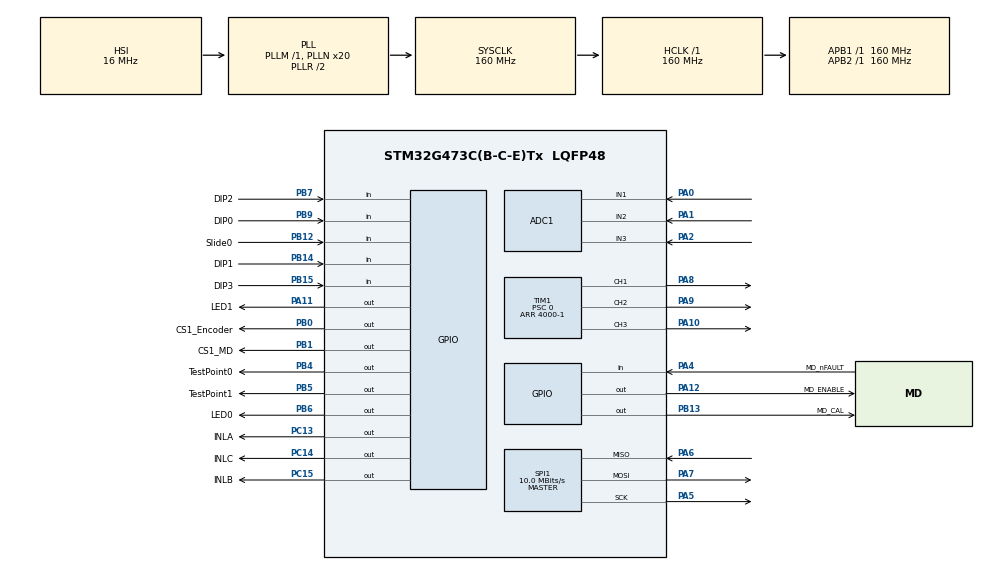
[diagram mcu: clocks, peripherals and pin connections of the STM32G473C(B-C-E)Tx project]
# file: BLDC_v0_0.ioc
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ADC1.DiscontinuousConvMode=DISABLE
ADC1.EnableInjectedConversion=ENABLE
ADC1.EnableRegularConversion=DISABLE
ADC1.ExternalTrigInjecConv=ADC_EXTERNALTRIGINJEC_T1_TRGO2
ADC1.InjNumberOfConversion=3
ADC1.InjectedChannel-3\#ChannelInjectedConversion=ADC_CHANNEL_1
ADC1.InjectedChannel-4\#ChannelInjectedConversion=ADC_CHANNEL_2
ADC1.InjectedChannel-5\#ChannelInjectedConversion=ADC_CHANNEL_3
ADC1.InjectedOffsetNumber-3\#ChannelInjectedConversion=ADC_OFFSET_NONE
ADC1.InjectedOffsetNumber-4\#ChannelInjectedConversion=ADC_OFFSET_NONE
ADC1.InjectedOffsetNumber-5\#ChannelInjectedConversion=ADC_OFFSET_NONE
ADC1.InjectedRank-3\#ChannelInjectedConversion=1
ADC1.InjectedRank-4\#ChannelInjectedConversion=2
ADC1.InjectedRank-5\#ChannelInjectedConversion=3
ADC1.InjectedSamplingTime-3\#ChannelInjectedConversion=ADC_SAMPLETIME_12CYCLES_5
ADC1.InjectedSamplingTime-4\#ChannelInjectedConversion=ADC_SAMPLETIME_12CYCLES_5
ADC1.InjectedSamplingTime-5\#ChannelInjectedConversion=ADC_SAMPLETIME_12CYCLES_5
ADC1.OversamplingMode=DISABLE
ADC1.Rank1_Channel=ADC_CHANNEL_1
ADC1.Rank2_Channel=ADC_CHANNEL_2
ADC1.Rank3_Channel=ADC_CHANNEL_3
ADC1.master=1
Mcu.Family=STM32G4
Mcu.Name=STM32G473C(B-C-E)Tx
Mcu.Package=LQFP48
NVIC.ADC1_2_IRQn=true\:8\:0\:true\:false\:true\:true\:true\:true
NVIC.PriorityGroup=NVIC_PRIORITYGROUP_4
NVIC.TIM1_CC_IRQn=true\:7\:0\:true\:false\:true\:true\:true\:true
NVIC.TIM3_IRQn=true\:6\:0\:true\:false\:true\:true\:true\:true
PA0.Mode=IN1-Single-Ended
PA0.Signal=ADC1_IN1
PA1.Mode=IN2-Single-Ended
PA1.Signal=ADC1_IN2
PA10.Signal=S_TIM1_CH3
PA11.GPIO_Label=LED1
PA11.Signal=GPIO_Output
PA12.GPIO_Label=MD_ENABLE
PA12.Signal=GPIO_Output
PA13.Mode=Trace_Asynchronous_SW
PA13.Signal=SYS_JTMS-SWDIO
PA14.Mode=Trace_Asynchronous_SW
PA14.Signal=SYS_JTCK-SWCLK
PA2.Mode=IN3-Single-Ended
PA2.Signal=ADC1_IN3
PA4.GPIO_Label=MD_nFAULT
PA4.Signal=GPIO_Input
PA5.GPIO_Speed=GPIO_SPEED_FREQ_MEDIUM
PA5.Mode=Full_Duplex_Master
PA5.Signal=SPI1_SCK
PA6.GPIO_Speed=GPIO_SPEED_FREQ_MEDIUM
PA6.Mode=Full_Duplex_Master
PA6.Signal=SPI1_MISO
PA7.GPIO_Speed=GPIO_SPEED_FREQ_MEDIUM
PA7.Mode=Full_Duplex_Master
PA7.Signal=SPI1_MOSI
PA8.Signal=S_TIM1_CH1
PA9.Signal=S_TIM1_CH2
PB0.GPIO_Label=CS1_Encoder
PB0.PinState=GPIO_PIN_SET
PB0.Signal=GPIO_Output
PB1.GPIO_Label=CS1_MD
PB1.PinState=GPIO_PIN_SET
PB1.Signal=GPIO_Output
PB12.GPIO_Label=Slide0
PB12.Signal=GPIO_Input
PB13.GPIO_Label=MD_CAL
PB13.Signal=GPIO_Output
PB14.GPIO_Label=DIP1
PB14.Signal=GPIO_Input
PB15.GPIO_Label=DIP3
PB15.Signal=GPIO_Input
PB3.Mode=Trace_Asynchronous_SW
PB3.Signal=SYS_JTDO-SWO
PB4.GPIO_Label=TestPoint0
PB4.Signal=GPIO_Output
PB5.GPIO_Label=TestPoint1
PB5.Signal=GPIO_Output
PB6.GPIO_Label=LED0
PB6.Signal=GPIO_Output
PB7.GPIO_Label=DIP2
PB7.Signal=GPIO_Input
PB9.GPIO_Label=DIP0
PB9.Signal=GPIO_Input
PC13.GPIO_Label=INLA
PC13.Signal=GPIO_Output
PC14-OSC32_IN.GPIO_Label=INLC
PC14-OSC32_IN.Signal=GPIO_Output
PC15-OSC32_OUT.GPIO_Label=INLB
PC15-OSC32_OUT.Signal=GPIO_Output
PF0-OSC_IN.Mode=HSE-External-Oscillator
PF0-OSC_IN.Signal=RCC_OSC_IN
PF1-OSC_OUT.Mode=HSE-External-Oscillator
PF1-OSC_OUT.Signal=RCC_OSC_OUT
ProjectManager.HeapSize=0x200
ProjectManager.StackSize=0x400
ProjectManager.TargetToolchain=STM32CubeIDE
RCC.ADC12Freq_Value=160000000
RCC.ADC345Freq_Value=160000000
RCC.AHBFreq_Value=160000000
RCC.APB1Freq_Value=160000000
RCC.APB1TimFreq_Value=160000000
RCC.APB2Freq_Value=160000000
RCC.APB2TimFreq_Value=160000000
RCC.CortexFreq_Value=160000000
RCC.EXTERNAL_CLOCK_VALUE=12288000
RCC.HCLKFreq_Value=160000000
RCC.HSE_VALUE=16000000
RCC.HSI48_VALUE=48000000
RCC.HSI_VALUE=16000000
RCC.LSE_VALUE=32768
RCC.PLLN=20
RCC.SYSCLKFreq_VALUE=160000000
RCC.SYSCLKSource=RCC_SYSCLKSOURCE_PLLCLK
RCC.USBFreq_Value=160000000
RCC.VCOOutputFreq_Value=320000000
SH.S_TIM1_CH1.0=TIM1_CH1,PWM Generation1 CH1
SH.S_TIM1_CH2.0=TIM1_CH2,PWM Generation2 CH2
SH.S_TIM1_CH3.0=TIM1_CH3,PWM Generation3 CH3
SPI1.BaudRatePrescaler=SPI_BAUDRATEPRESCALER_16
SPI1.CLKPhase=SPI_PHASE_2EDGE
SPI1.CLKPolarity=SPI_POLARITY_LOW
SPI1.CalculateBaudRate=10.0 MBits/s
SPI1.DataSize=SPI_DATASIZE_16BIT
SPI1.Direction=SPI_DIRECTION_2LINES
SPI1.Mode=SPI_MODE_MASTER
SPI1.VirtualType=VM_MASTER
TIM1.Channel-PWM\ Generation1\ CH1=TIM_CHANNEL_1
TIM1.Channel-PWM\ Generation2\ CH2=TIM_CHANNEL_2
TIM1.Channel-PWM\ Generation3\ CH3=TIM_CHANNEL_3
TIM1.Channel-PWM\ Generation4\ No\ Output=TIM_CHANNEL_4
TIM1.CounterMode=TIM_COUNTERMODE_CENTERALIGNED3
TIM1.OCMode_PWM-PWM\ Generation4\ No\ Output=TIM_OCMODE_PWM2
TIM1.PeriodNoDither=4000-1
TIM1.Prescaler=0
TIM1.TIM_MasterOutputTrigger=TIM_TRGO_UPDATE
TIM1.TIM_MasterOutputTrigger2=TIM_TRGO2_OC4REF
TIM3.Channel-PWM\ Generation1\ CH1=TIM_CHANNEL_1
TIM3.Channel-PWM\ Generation2\ CH2=TIM_CHANNEL_2
TIM3.Channel-PWM\ Generation3\ CH3=TIM_CHANNEL_3
TIM3.PeriodNoDither=65536-1
TIM3.Prescaler=15
VP_CORDIC_VS_CORDIC.Mode=CORDIC_Activate
VP_FMAC_VS_FMAC.Mode=FMAC_Activate
VP_SYS_VS_DBSignals.Mode=DisableDeadBatterySignals
VP_TIM1_VS_ClockSourceINT.Mode=Internal
VP_TIM1_VS_no_output4.Mode=PWM Generation4 No Output
VP_TIM3_VS_ClockSourceINT.Mode=Internal
board=custom

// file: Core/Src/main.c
/* USER CODE BEGIN Header */
/**
  ******************************************************************************
  * @file           : main.c
  * @brief          : Main program body
  ******************************************************************************
  * @attention
  *
  * Copyright (c) 2025 STMicroelectronics.
  * All rights reserved.
  *
  * This software is licensed under terms that can be found in the LICENSE file
  * in the root directory of this software component.
  * If no LICENSE file comes with this software, it is provided AS-IS.
  *
  ******************************************************************************
  */
/* USER CODE END Header */
#include "main.h"

/* USER CODE BEGIN Includes */

#include "Driver.h"
#include "AS5047P.h"
#include "DRV8323S.h"

#include <stdio.h>
#include <stdlib.h>
#include <stdbool.h>
#include <math.h>
#include <stm32g4xx_hal_cordic.h>

/* USER CODE END Includes */

ADC_HandleTypeDef hadc1;

CORDIC_HandleTypeDef hcordic;

FMAC_HandleTypeDef hfmac;

SPI_HandleTypeDef hspi1;

TIM_HandleTypeDef htim1;
TIM_HandleTypeDef htim3;

void SystemClock_Config(void);
static void MX_GPIO_Init(void);
static void MX_SPI1_Init(void);
static void MX_TIM3_Init(void);
static void MX_TIM1_Init(void);
static void MX_ADC1_Init(void);
static void MX_CORDIC_Init(void);
static void MX_FMAC_Init(void);

int main(void)
{

  /* MCU Configuration--------------------------------------------------------*/

  /* Reset of all peripherals, Initializes the Flash interface and the Systick. */
  HAL_Init();

  /* Configure the system clock */
  SystemClock_Config();

  /* Initialize all configured peripherals */
  MX_GPIO_Init();
  MX_SPI1_Init();
  MX_TIM3_Init();
  MX_TIM1_Init();
  MX_ADC1_Init();
  MX_CORDIC_Init();
  MX_FMAC_Init();

  /* Infinite loop */
  while (1)
  {

  }
}

void SystemClock_Config(void)
{
  RCC_OscInitTypeDef RCC_OscInitStruct = {0};
  RCC_ClkInitTypeDef RCC_ClkInitStruct = {0};

  /** Configure the main internal regulator output voltage
  */
  HAL_PWREx_ControlVoltageScaling(PWR_REGULATOR_VOLTAGE_SCALE1_BOOST);

  /** Initializes the RCC Oscillators according to the specified parameters
  * in the RCC_OscInitTypeDef structure.
  */
  RCC_OscInitStruct.OscillatorType = RCC_OSCILLATORTYPE_HSI;
  RCC_OscInitStruct.HSIState = RCC_HSI_ON;
  RCC_OscInitStruct.HSICalibrationValue = RCC_HSICALIBRATION_DEFAULT;
  RCC_OscInitStruct.PLL.PLLState = RCC_PLL_ON;
  RCC_OscInitStruct.PLL.PLLSource = RCC_PLLSOURCE_HSI;
  RCC_OscInitStruct.PLL.PLLM = RCC_PLLM_DIV1;
  RCC_OscInitStruct.PLL.PLLN = 20;
  RCC_OscInitStruct.PLL.PLLP = RCC_PLLP_DIV2;
  RCC_OscInitStruct.PLL.PLLQ = RCC_PLLQ_DIV2;
  RCC_OscInitStruct.PLL.PLLR = RCC_PLLR_DIV2;
  if (HAL_RCC_OscConfig(&RCC_OscInitStruct) != HAL_OK)
  {
    Error_Handler();
  }

  /** Initializes the CPU, AHB and APB buses clocks
  */
  RCC_ClkInitStruct.ClockType = RCC_CLOCKTYPE_HCLK|RCC_CLOCKTYPE_SYSCLK
                              |RCC_CLOCKTYPE_PCLK1|RCC_CLOCKTYPE_PCLK2;
  RCC_ClkInitStruct.SYSCLKSource = RCC_SYSCLKSOURCE_PLLCLK;
  RCC_ClkInitStruct.AHBCLKDivider = RCC_SYSCLK_DIV1;
  RCC_ClkInitStruct.APB1CLKDivider = RCC_HCLK_DIV1;
  RCC_ClkInitStruct.APB2CLKDivider = RCC_HCLK_DIV1;

  if (HAL_RCC_ClockConfig(&RCC_ClkInitStruct, FLASH_LATENCY_4) != HAL_OK)
  {
    Error_Handler();
  }
}

static void MX_ADC1_Init(void)
{

  ADC_MultiModeTypeDef multimode = {0};
  ADC_InjectionConfTypeDef sConfigInjected = {0};

  /** Common config
  */
  hadc1.Instance = ADC1;
  hadc1.Init.ClockPrescaler = ADC_CLOCK_SYNC_PCLK_DIV4;
  hadc1.Init.Resolution = ADC_RESOLUTION_12B;
  hadc1.Init.DataAlign = ADC_DATAALIGN_RIGHT;
  hadc1.Init.GainCompensation = 0;
  hadc1.Init.ScanConvMode = ADC_SCAN_ENABLE;
  hadc1.Init.EOCSelection = ADC_EOC_SINGLE_CONV;
  hadc1.Init.LowPowerAutoWait = DISABLE;
  hadc1.Init.ContinuousConvMode = DISABLE;
  hadc1.Init.NbrOfConversion = 1;
  hadc1.Init.DiscontinuousConvMode = DISABLE;
  hadc1.Init.DMAContinuousRequests = DISABLE;
  hadc1.Init.Overrun = ADC_OVR_DATA_PRESERVED;
  hadc1.Init.OversamplingMode = DISABLE;
  if (HAL_ADC_Init(&hadc1) != HAL_OK)
  {
    Error_Handler();
  }

  /** Configure the ADC multi-mode
  */
  multimode.Mode = ADC_MODE_INDEPENDENT;
  if (HAL_ADCEx_MultiModeConfigChannel(&hadc1, &multimode) != HAL_OK)
  {
    Error_Handler();
  }

  /** Configure Injected Channel
  */
  sConfigInjected.InjectedChannel = ADC_CHANNEL_1;
  sConfigInjected.InjectedRank = ADC_INJECTED_RANK_1;
  sConfigInjected.InjectedSamplingTime = ADC_SAMPLETIME_12CYCLES_5;
  sConfigInjected.InjectedSingleDiff = ADC_SINGLE_ENDED;
  sConfigInjected.InjectedOffsetNumber = ADC_OFFSET_NONE;
  sConfigInjected.InjectedOffset = 0;
  sConfigInjected.InjectedNbrOfConversion = 3;
  sConfigInjected.InjectedDiscontinuousConvMode = DISABLE;
  sConfigInjected.AutoInjectedConv = DISABLE;
  sConfigInjected.QueueInjectedContext = DISABLE;
  sConfigInjected.ExternalTrigInjecConv = ADC_EXTERNALTRIGINJEC_T1_TRGO2;
  sConfigInjected.ExternalTrigInjecConvEdge = ADC_EXTERNALTRIGINJECCONV_EDGE_RISING;
  sConfigInjected.InjecOversamplingMode = DISABLE;
  if (HAL_ADCEx_InjectedConfigChannel(&hadc1, &sConfigInjected) != HAL_OK)
  {
    Error_Handler();
  }

  /** Configure Injected Channel
  */
  sConfigInjected.InjectedChannel = ADC_CHANNEL_2;
  sConfigInjected.InjectedRank = ADC_INJECTED_RANK_2;
  if (HAL_ADCEx_InjectedConfigChannel(&hadc1, &sConfigInjected) != HAL_OK)
  {
    Error_Handler();
  }

  /** Configure Injected Channel
  */
  sConfigInjected.InjectedChannel = ADC_CHANNEL_3;
  sConfigInjected.InjectedRank = ADC_INJECTED_RANK_3;
  if (HAL_ADCEx_InjectedConfigChannel(&hadc1, &sConfigInjected) != HAL_OK)
  {
    Error_Handler();
  }

}

static void MX_CORDIC_Init(void)
{

  hcordic.Instance = CORDIC;
  if (HAL_CORDIC_Init(&hcordic) != HAL_OK)
  {
    Error_Handler();
  }

}

static void MX_FMAC_Init(void)
{

  hfmac.Instance = FMAC;
  if (HAL_FMAC_Init(&hfmac) != HAL_OK)
  {
    Error_Handler();
  }

}

static void MX_SPI1_Init(void)
{

  /* SPI1 parameter configuration*/
  hspi1.Instance = SPI1;
  hspi1.Init.Mode = SPI_MODE_MASTER;
  hspi1.Init.Direction = SPI_DIRECTION_2LINES;
  hspi1.Init.DataSize = SPI_DATASIZE_16BIT;
  hspi1.Init.CLKPolarity = SPI_POLARITY_LOW;
  hspi1.Init.CLKPhase = SPI_PHASE_2EDGE;
  hspi1.Init.NSS = SPI_NSS_SOFT;
  hspi1.Init.BaudRatePrescaler = SPI_BAUDRATEPRESCALER_16;
  hspi1.Init.FirstBit = SPI_FIRSTBIT_MSB;
  hspi1.Init.TIMode = SPI_TIMODE_DISABLE;
  hspi1.Init.CRCCalculation = SPI_CRCCALCULATION_DISABLE;
  hspi1.Init.CRCPolynomial = 7;
  hspi1.Init.CRCLength = SPI_CRC_LENGTH_DATASIZE;
  hspi1.Init.NSSPMode = SPI_NSS_PULSE_DISABLE;
  if (HAL_SPI_Init(&hspi1) != HAL_OK)
  {
    Error_Handler();
  }

}

static void MX_TIM1_Init(void)
{

  TIM_ClockConfigTypeDef sClockSourceConfig = {0};
  TIM_MasterConfigTypeDef sMasterConfig = {0};
  TIM_OC_InitTypeDef sConfigOC = {0};
  TIM_BreakDeadTimeConfigTypeDef sBreakDeadTimeConfig = {0};

  htim1.Instance = TIM1;
  htim1.Init.Prescaler = 0;
  htim1.Init.CounterMode = TIM_COUNTERMODE_CENTERALIGNED3;
  htim1.Init.Period = 3999;
  htim1.Init.ClockDivision = TIM_CLOCKDIVISION_DIV1;
  htim1.Init.RepetitionCounter = 0;
  htim1.Init.AutoReloadPreload = TIM_AUTORELOAD_PRELOAD_DISABLE;
  if (HAL_TIM_Base_Init(&htim1) != HAL_OK)
  {
    Error_Handler();
  }
  sClockSourceConfig.ClockSource = TIM_CLOCKSOURCE_INTERNAL;
  if (HAL_TIM_ConfigClockSource(&htim1, &sClockSourceConfig) != HAL_OK)
  {
    Error_Handler();
  }
  if (HAL_TIM_PWM_Init(&htim1) != HAL_OK)
  {
    Error_Handler();
  }
  sMasterConfig.MasterOutputTrigger = TIM_TRGO_UPDATE;
  sMasterConfig.MasterOutputTrigger2 = TIM_TRGO2_OC4REF;
  sMasterConfig.MasterSlaveMode = TIM_MASTERSLAVEMODE_DISABLE;
  if (HAL_TIMEx_MasterConfigSynchronization(&htim1, &sMasterConfig) != HAL_OK)
  {
    Error_Handler();
  }
  sConfigOC.OCMode = TIM_OCMODE_PWM1;
  sConfigOC.Pulse = 0;
  sConfigOC.OCPolarity = TIM_OCPOLARITY_HIGH;
  sConfigOC.OCNPolarity = TIM_OCNPOLARITY_HIGH;
  sConfigOC.OCFastMode = TIM_OCFAST_DISABLE;
  sConfigOC.OCIdleState = TIM_OCIDLESTATE_RESET;
  sConfigOC.OCNIdleState = TIM_OCNIDLESTATE_RESET;
  if (HAL_TIM_PWM_ConfigChannel(&htim1, &sConfigOC, TIM_CHANNEL_1) != HAL_OK)
  {
    Error_Handler();
  }
  if (HAL_TIM_PWM_ConfigChannel(&htim1, &sConfigOC, TIM_CHANNEL_2) != HAL_OK)
  {
    Error_Handler();
  }
  if (HAL_TIM_PWM_ConfigChannel(&htim1, &sConfigOC, TIM_CHANNEL_3) != HAL_OK)
  {
    Error_Handler();
  }
  sConfigOC.OCMode = TIM_OCMODE_PWM2;
  if (HAL_TIM_PWM_ConfigChannel(&htim1, &sConfigOC, TIM_CHANNEL_4) != HAL_OK)
  {
    Error_Handler();
  }
  sBreakDeadTimeConfig.OffStateRunMode = TIM_OSSR_DISABLE;
  sBreakDeadTimeConfig.OffStateIDLEMode = TIM_OSSI_DISABLE;
  sBreakDeadTimeConfig.LockLevel = TIM_LOCKLEVEL_OFF;
  sBreakDeadTimeConfig.DeadTime = 0;
  sBreakDeadTimeConfig.BreakState = TIM_BREAK_DISABLE;
  sBreakDeadTimeConfig.BreakPolarity = TIM_BREAKPOLARITY_HIGH;
  sBreakDeadTimeConfig.BreakFilter = 0;
  sBreakDeadTimeConfig.BreakAFMode = TIM_BREAK_AFMODE_INPUT;
  sBreakDeadTimeConfig.Break2State = TIM_BREAK2_DISABLE;
  sBreakDeadTimeConfig.Break2Polarity = TIM_BREAK2POLARITY_HIGH;
  sBreakDeadTimeConfig.Break2Filter = 0;
  sBreakDeadTimeConfig.Break2AFMode = TIM_BREAK_AFMODE_INPUT;
  sBreakDeadTimeConfig.AutomaticOutput = TIM_AUTOMATICOUTPUT_DISABLE;
  if (HAL_TIMEx_ConfigBreakDeadTime(&htim1, &sBreakDeadTimeConfig) != HAL_OK)
  {
    Error_Handler();
  }
  HAL_TIM_MspPostInit(&htim1);

}

static void MX_TIM3_Init(void)
{

  TIM_ClockConfigTypeDef sClockSourceConfig = {0};
  TIM_MasterConfigTypeDef sMasterConfig = {0};

  htim3.Instance = TIM3;
  htim3.Init.Prescaler = 15;
  htim3.Init.CounterMode = TIM_COUNTERMODE_UP;
  htim3.Init.Period = 65535;
  htim3.Init.ClockDivision = TIM_CLOCKDIVISION_DIV1;
  htim3.Init.AutoReloadPreload = TIM_AUTORELOAD_PRELOAD_DISABLE;
  if (HAL_TIM_Base_Init(&htim3) != HAL_OK)
  {
    Error_Handler();
  }
  sClockSourceConfig.ClockSource = TIM_CLOCKSOURCE_INTERNAL;
  if (HAL_TIM_ConfigClockSource(&htim3, &sClockSourceConfig) != HAL_OK)
  {
    Error_Handler();
  }
  sMasterConfig.MasterOutputTrigger = TIM_TRGO_RESET;
  sMasterConfig.MasterSlaveMode = TIM_MASTERSLAVEMODE_DISABLE;
  if (HAL_TIMEx_MasterConfigSynchronization(&htim3, &sMasterConfig) != HAL_OK)
  {
    Error_Handler();
  }

}

static void MX_GPIO_Init(void)
{
  GPIO_InitTypeDef GPIO_InitStruct = {0};

  /* GPIO Ports Clock Enable */
  __HAL_RCC_GPIOC_CLK_ENABLE();
  __HAL_RCC_GPIOF_CLK_ENABLE();
  __HAL_RCC_GPIOA_CLK_ENABLE();
  __HAL_RCC_GPIOB_CLK_ENABLE();

  /*Configure GPIO pin Output Level */
  HAL_GPIO_WritePin(GPIOC, INLA_Pin|INLC_Pin|INLB_Pin, GPIO_PIN_RESET);

  /*Configure GPIO pin Output Level */
  HAL_GPIO_WritePin(GPIOB, CS1_Encoder_Pin|CS1_MD_Pin, GPIO_PIN_SET);

  /*Configure GPIO pin Output Level */
  HAL_GPIO_WritePin(GPIOB, MD_CAL_Pin|TestPoint0_Pin|TestPoint1_Pin|LED0_Pin, GPIO_PIN_RESET);

  /*Configure GPIO pin Output Level */
  HAL_GPIO_WritePin(GPIOA, LED1_Pin|MD_ENABLE_Pin, GPIO_PIN_RESET);

  /*Configure GPIO pins : INLA_Pin INLC_Pin INLB_Pin */
  GPIO_InitStruct.Pin = INLA_Pin|INLC_Pin|INLB_Pin;
  GPIO_InitStruct.Mode = GPIO_MODE_OUTPUT_PP;
  GPIO_InitStruct.Pull = GPIO_NOPULL;
  GPIO_InitStruct.Speed = GPIO_SPEED_FREQ_LOW;
  HAL_GPIO_Init(GPIOC, &GPIO_InitStruct);

  /*Configure GPIO pin : MD_nFAULT_Pin */
  GPIO_InitStruct.Pin = MD_nFAULT_Pin;
  GPIO_InitStruct.Mode = GPIO_MODE_INPUT;
  GPIO_InitStruct.Pull = GPIO_NOPULL;
  HAL_GPIO_Init(MD_nFAULT_GPIO_Port, &GPIO_InitStruct);

  /*Configure GPIO pins : CS1_Encoder_Pin CS1_MD_Pin MD_CAL_Pin TestPoint0_Pin
                           TestPoint1_Pin LED0_Pin */
  GPIO_InitStruct.Pin = CS1_Encoder_Pin|CS1_MD_Pin|MD_CAL_Pin|TestPoint0_Pin
                          |TestPoint1_Pin|LED0_Pin;
  GPIO_InitStruct.Mode = GPIO_MODE_OUTPUT_PP;
  GPIO_InitStruct.Pull = GPIO_NOPULL;
  GPIO_InitStruct.Speed = GPIO_SPEED_FREQ_LOW;
  HAL_GPIO_Init(GPIOB, &GPIO_InitStruct);

  /*Configure GPIO pins : Slide0_Pin DIP1_Pin DIP3_Pin DIP2_Pin
                           DIP0_Pin */
  GPIO_InitStruct.Pin = Slide0_Pin|DIP1_Pin|DIP3_Pin|DIP2_Pin
                          |DIP0_Pin;
  GPIO_InitStruct.Mode = GPIO_MODE_INPUT;
  GPIO_InitStruct.Pull = GPIO_NOPULL;
  HAL_GPIO_Init(GPIOB, &GPIO_InitStruct);

  /*Configure GPIO pins : LED1_Pin MD_ENABLE_Pin */
  GPIO_InitStruct.Pin = LED1_Pin|MD_ENABLE_Pin;
  GPIO_InitStruct.Mode = GPIO_MODE_OUTPUT_PP;
  GPIO_InitStruct.Pull = GPIO_NOPULL;
  GPIO_InitStruct.Speed = GPIO_SPEED_FREQ_LOW;
  HAL_GPIO_Init(GPIOA, &GPIO_InitStruct);

}

void Error_Handler(void)
{
  __disable_irq();
  while (1)
  {
  }
}
